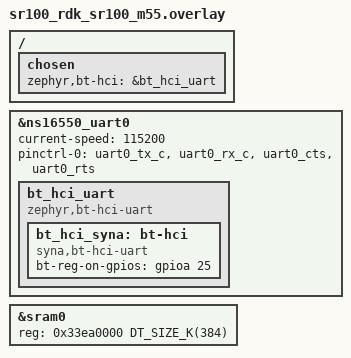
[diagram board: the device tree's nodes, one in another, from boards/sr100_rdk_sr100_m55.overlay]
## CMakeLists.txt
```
# Copyright (c) 2026 Synaptics Incorporated
#
# SPDX-License-Identifier: Apache-2.0

cmake_minimum_required(VERSION 3.20.0)

find_package(Zephyr REQUIRED HINTS $ENV{ZEPHYR_BASE})
project(bt_observer)

target_sources(app PRIVATE src/main.c)
```

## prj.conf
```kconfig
# Copyright (c) 2026 Synaptics Incorporated
#
# SPDX-License-Identifier: Apache-2.0

# Console
CONFIG_CONSOLE=y
CONFIG_UART_CONSOLE=y
CONFIG_PRINTK=y
CONFIG_STDOUT_CONSOLE=y

# Logging
CONFIG_LOG=y
CONFIG_LOG_DEFAULT_LEVEL=3

# Bluetooth HOST stack
CONFIG_BT=y
CONFIG_BT_OBSERVER=y

# HCI H:4 UART transport
CONFIG_BT_H4=y

# Synaptics SYNA vendor setup (REGON + patchram)
CONFIG_BT_HCI_SYNA=y

# GPIO (for BT_REGON)
CONFIG_GPIO=y

# UART interrupt-driven mode (required by H4 HCI driver)
CONFIG_UART_INTERRUPT_DRIVEN=y

# Extend SRAM to full VM0 region (384KB)
CONFIG_SRAM_SIZE=384


# XIP: run from SRAM
CONFIG_XIP=n
CONFIG_UART_NS16550_VARIANT_NS16750=y

# Stack sizes — BT init (patchram download) needs significant depth
# We use bt_enable(callback) so init runs in BT workq, but keep main larger too.
CONFIG_MAIN_STACK_SIZE=4096
CONFIG_BT_RX_STACK_SIZE=4096

# SYNA WRITE_RAM patchram records can be up to 255 bytes.
# Default BT_BUF_CMD_TX_SIZE=65 is too small → buffer overflow → chip returns
# INVALID_PARAM (0x12) → bt_hci_cmd_send_sync returns -EINVAL (-22).
CONFIG_BT_BUF_CMD_TX_SIZE=255
```

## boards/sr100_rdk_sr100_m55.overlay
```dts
/*
 * Copyright (c) 2026 Synaptics Incorporated
 *
 * SPDX-License-Identifier: Apache-2.0
 */

/*
 * sr110_rdk.overlay — BLE Broadcaster / Observer shared overlay
 *
 * Enables UART0 as the HCI transport for SYNA.
 * The bt_hci_uart wrapper + syna,bt-hci-uart child expose UART0
 * to the Zephyr BT H:4 driver.  GPIO25 is BT_REGON.
 */

/ {
	chosen {
		zephyr,bt-hci = &bt_hci_uart;
	};
};

&ns16550_uart0 {
	status = "okay";
	current-speed = <115200>;
	pinctrl-0 = <&uart0_tx_c &uart0_rx_c &uart0_cts &uart0_rts>;
	pinctrl-names = "default";

	bt_hci_uart: bt_hci_uart {
		compatible = "zephyr,bt-hci-uart";
		status = "okay";

		bt_hci_syna: bt-hci {
			compatible = "syna,bt-hci-uart";
			status = "okay";
			bt-reg-on-gpios = <&gpioa 25 GPIO_ACTIVE_HIGH>;
		};
	};
};

/*
 * Extend SRAM to cover the full VM0 region (0x33ea0000..0x33F00000 = 384KB).
 * The BT HOST stack + patchram together require more than the 128KB default.
 */
&sram0 {
	reg = <0x33ea0000 DT_SIZE_K(384)>;
	ranges = <0x0 0x33ea0000 DT_SIZE_K(384)>;
};
```

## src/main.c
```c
/*
 * Copyright (c) 2026 Synaptics Incorporated
 *
 * SPDX-License-Identifier: Apache-2.0
 */

/* main.c - BLE Observer sample for SR110 RDK + SYNA
 *
 * Scans for nearby BLE advertisers and prints address, RSSI, and AD data.
 * Pairs with the broadcaster sample.
 */

#include <zephyr/kernel.h>
#include <zephyr/sys/printk.h>
#include <zephyr/bluetooth/bluetooth.h>
#include <zephyr/bluetooth/hci.h>

static void device_found(const bt_addr_le_t *addr, int8_t rssi, uint8_t type,
			 struct net_buf_simple *ad)
{
	char addr_str[BT_ADDR_LE_STR_LEN];

	bt_addr_le_to_str(addr, addr_str, sizeof(addr_str));
	printk("Found: %s RSSI=%d type=%u adlen=%u\n",
	       addr_str, rssi, type, ad->len);
}

/* Semaphore signalled from bt_ready() once the BT stack is up */
static K_SEM_DEFINE(ble_init_ok, 0, 1);

static void bt_ready(int err)
{
	if (err) {
		printk("Bluetooth init failed (err %d)\n", err);
		return;
	}
	printk("Bluetooth initialized\n");
	k_sem_give(&ble_init_ok);
}

int main(void)
{
	int err;

	printk("BLE Observer starting (SYNA on SR110)\n");

	/*
	 * Use the async callback form so that bt_init() (which downloads
	 * patchram) runs in the BT work-queue thread with its own large
	 * stack rather than on the 1 KB main stack.
	 */
	err = bt_enable(bt_ready);
	if (err) {
		printk("bt_enable failed (err %d)\n", err);
		return 0;
	}

	/* Wait for the BT work-queue to finish initialising the controller */
	k_sem_take(&ble_init_ok, K_FOREVER);

	/* Continuous passive scan, 30 ms window, duplicate filtering */
	struct bt_le_scan_param scan_param = {
		.type    = BT_LE_SCAN_TYPE_PASSIVE,
		.options = BT_LE_SCAN_OPT_FILTER_DUPLICATE,
		.interval = BT_GAP_SCAN_FAST_INTERVAL_MIN,
		.window   = BT_GAP_SCAN_FAST_WINDOW,
	};

	err = bt_le_scan_start(&scan_param, device_found);
	if (err) {
		printk("Scan start failed (err %d)\n", err);
		return 0;
	}

	printk("Scanning started\n");

	/* Scan indefinitely */
	while (1) {
		k_msleep(1000);
	}

	return 0;
}
```
